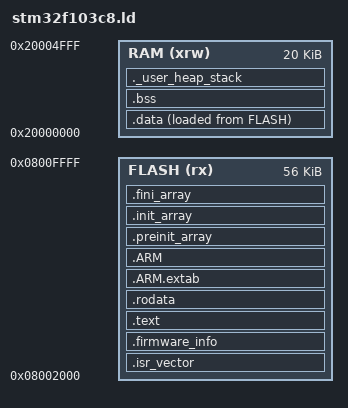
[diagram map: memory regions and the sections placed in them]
/*
******************************************************************************
**
** @file        : LinkerScript.ld
**
** @author      : Auto-generated by STM32CubeIDE
**
** @brief       : Linker script for STM32F103C8Tx Device from STM32F1 series
**                      64Kbytes FLASH
**                      20Kbytes RAM
**
**                Set heap size, stack size and stack location according
**                to application requirements.
**
**                Set memory bank area and size if external memory is used
**
**  Target      : STMicroelectronics STM32
**
**  Distribution: The file is distributed as is, without any warranty
**                of any kind.
**
******************************************************************************
** @attention
**
** <h2><center>&copy; Copyright (c) 2021 STMicroelectronics.
** All rights reserved.</center></h2>
**
** This software component is licensed by ST under BSD 3-Clause license,
** the "License"; You may not use this file except in compliance with the
** License. You may obtain a copy of the License at:
**                        opensource.org/licenses/BSD-3-Clause
**
******************************************************************************
*/

/*
 * Based on tool-ldscripts-ststm32 0.3.0, stm32f1/STM32F103C8TX_FLASH.ld.
 * Local change: preinit/init/fini pointer tables are READONLY in FLASH.
 * Uses GNU ld READONLY syntax supported by the pinned GCC 14.2.1 toolchain.
 * Application moved above the 8 KB loader; startup/heap/stack symbols retained.
 *
 * Copyright (c) 2021 STMicroelectronics. All rights reserved.
 *
 * Redistribution and use in source and binary forms, with or without
 * modification, are permitted provided that the following conditions are met:
 *
 * 1. Redistributions of source code must retain the above copyright notice,
 *    this list of conditions and the following disclaimer.
 * 2. Redistributions in binary form must reproduce the above copyright notice,
 *    this list of conditions and the following disclaimer in the documentation
 *    and/or other materials provided with the distribution.
 * 3. Neither the name of the copyright holder nor the names of its contributors
 *    may be used to endorse or promote products derived from this software
 *    without specific prior written permission.
 *
 * THIS SOFTWARE IS PROVIDED BY THE COPYRIGHT HOLDERS AND CONTRIBUTORS "AS IS"
 * AND ANY EXPRESS OR IMPLIED WARRANTIES, INCLUDING, BUT NOT LIMITED TO, THE
 * IMPLIED WARRANTIES OF MERCHANTABILITY AND FITNESS FOR A PARTICULAR PURPOSE
 * ARE DISCLAIMED. IN NO EVENT SHALL THE COPYRIGHT HOLDER OR CONTRIBUTORS BE
 * LIABLE FOR ANY DIRECT, INDIRECT, INCIDENTAL, SPECIAL, EXEMPLARY, OR
 * CONSEQUENTIAL DAMAGES (INCLUDING, BUT NOT LIMITED TO, PROCUREMENT OF
 * SUBSTITUTE GOODS OR SERVICES; LOSS OF USE, DATA, OR PROFITS; OR BUSINESS
 * INTERRUPTION) HOWEVER CAUSED AND ON ANY THEORY OF LIABILITY, WHETHER IN
 * CONTRACT, STRICT LIABILITY, OR TORT (INCLUDING NEGLIGENCE OR OTHERWISE)
 * ARISING IN ANY WAY OUT OF THE USE OF THIS SOFTWARE, EVEN IF ADVISED OF THE
 * POSSIBILITY OF SUCH DAMAGE.
 */

/* Entry Point */
ENTRY(Reset_Handler)

/* Initial stack pointer at the top of RAM (0x20005000); stack grows down. */
_estack = ORIGIN(RAM) + LENGTH(RAM); /* end of "RAM" Ram type memory */

_Min_Heap_Size = 0x200; /* reserve at least 512 bytes at link time */
_Min_Stack_Size = 0x400; /* reserve at least 1024 bytes at link time */

/* Assumed F103C8 memory sizes. First 8 KB belongs to bootloader.ld; remaining 56 KB is application. */
MEMORY
{
  RAM    (xrw)    : ORIGIN = 0x20000000,   LENGTH = 20K
  FLASH    (rx)    : ORIGIN = 0x8002000,   LENGTH = 56K
}

/* Sections */
SECTIONS
{
  /* The startup code into "FLASH" Rom type memory */
  .isr_vector :
  {
    . = ALIGN(4);
    KEEP(*(.isr_vector)) /* Reset/IRQ vectors must survive section garbage collection. */
    . = ALIGN(4);
  } >FLASH

  /* Fixed image identity read by bootloader/uploader before activation. */
  .firmware_info ORIGIN(FLASH) + 0x200 :
  {
    KEEP(*(.firmware_info))
  } >FLASH

  /* The program code and other data into "FLASH" Rom type memory */
  .text :
  {
    . = ALIGN(4);
    *(.text)           /* .text sections (code) */
    *(.text*)          /* .text* sections (code) */
    *(.glue_7)         /* glue arm to thumb code */
    *(.glue_7t)        /* glue thumb to arm code */
    *(.eh_frame)

    KEEP (*(.init))
    KEEP (*(.fini))

    . = ALIGN(4);
    _etext = .;        /* define a global symbols at end of code */
  } >FLASH

  /* Constant data into "FLASH" Rom type memory */
  .rodata :
  {
    . = ALIGN(4);
    *(.rodata)         /* .rodata sections (constants, strings, etc.) */
    *(.rodata*)        /* .rodata* sections (constants, strings, etc.) */
    . = ALIGN(4);
  } >FLASH

  .ARM.extab   : {
    . = ALIGN(4);
    *(.ARM.extab* .gnu.linkonce.armextab.*)
    . = ALIGN(4);
  } >FLASH

  .ARM : {
    . = ALIGN(4);
    __exidx_start = .;
    *(.ARM.exidx*)
    __exidx_end = .;
    . = ALIGN(4);
  } >FLASH

  /* Runtime startup/finalisation pointers live in flash and are never written
     by the application. READONLY prevents a writable/executable flash segment. */
  .preinit_array (READONLY) :
  {
    . = ALIGN(4);
    PROVIDE_HIDDEN (__preinit_array_start = .);
    KEEP (*(.preinit_array*))
    PROVIDE_HIDDEN (__preinit_array_end = .);
    . = ALIGN(4);
  } >FLASH

  .init_array (READONLY) :
  {
    . = ALIGN(4);
    PROVIDE_HIDDEN (__init_array_start = .);
    KEEP (*(SORT(.init_array.*)))
    KEEP (*(.init_array*))
    PROVIDE_HIDDEN (__init_array_end = .);
    . = ALIGN(4);
  } >FLASH

  .fini_array (READONLY) :
  {
    . = ALIGN(4);
    PROVIDE_HIDDEN (__fini_array_start = .);
    KEEP (*(SORT(.fini_array.*)))
    KEEP (*(.fini_array*))
    PROVIDE_HIDDEN (__fini_array_end = .);
    . = ALIGN(4);
  } >FLASH

  /* Startup copies initial .data bytes from this flash load address to RAM. */
  _sidata = LOADADDR(.data);

  /* Initialized data sections into "RAM" Ram type memory */
  .data :
  {
    . = ALIGN(4);
    _sdata = .;        /* create a global symbol at data start */
    *(.data)           /* .data sections */
    *(.data*)          /* .data* sections */
    *(.RamFunc)        /* .RamFunc sections */
    *(.RamFunc*)       /* .RamFunc* sections */

    . = ALIGN(4);
    _edata = .;        /* define a global symbol at data end */

  } >RAM AT> FLASH

  /* Startup clears .bss to zero before main, including the feeder state. */
  . = ALIGN(4);
  .bss :
  {
    /* This is used by the startup in order to initialize the .bss section */
    _sbss = .;         /* define a global symbol at bss start */
    __bss_start__ = _sbss;
    *(.bss)
    *(.bss*)
    *(COMMON)

    . = ALIGN(4);
    _ebss = .;         /* define a global symbol at bss end */
    __bss_end__ = _ebss;
  } >RAM

  /* Link-time minimum-space check, not a runtime stack/heap collision guard.
     Actual interrupt nesting and library allocations still consume RAM. */
  ._user_heap_stack :
  {
    . = ALIGN(8);
    PROVIDE ( end = . );
    PROVIDE ( _end = . );
    . = . + _Min_Heap_Size;
    . = . + _Min_Stack_Size;
    . = ALIGN(8);
  } >RAM

  /* Remove information from the compiler libraries */
  /DISCARD/ :
  {
    libc.a ( * )
    libm.a ( * )
    libgcc.a ( * )
  }

  .ARM.attributes 0 : { *(.ARM.attributes) }
}
